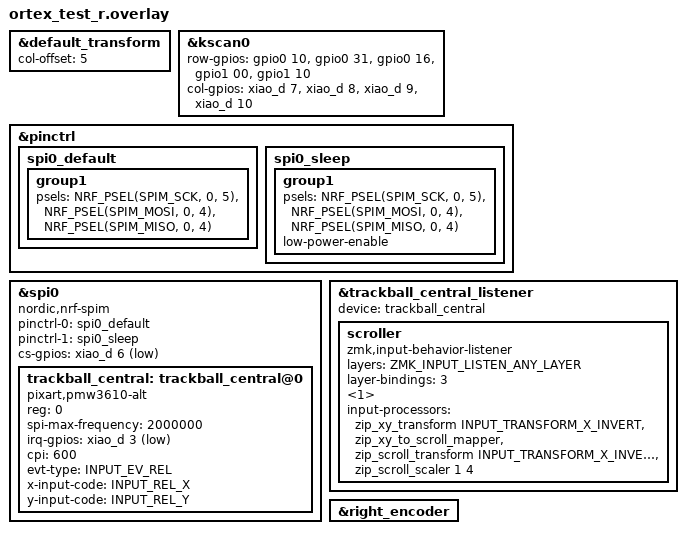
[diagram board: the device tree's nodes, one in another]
#include "ortex_test.dtsi"
#include <input/processors.dtsi>
#include <zephyr/dt-bindings/input/input-event-codes.h>

&default_transform {
    col-offset = <5>;
};

&kscan0 {        
        row-gpios
            = <&gpio0 10 GPIO_ACTIVE_HIGH>
            , <&gpio0 31 GPIO_ACTIVE_HIGH> 
            , <&gpio0 16 GPIO_ACTIVE_HIGH> 
            , <&gpio1 00 GPIO_ACTIVE_HIGH> 
            , <&gpio1 10 GPIO_ACTIVE_HIGH> 
            ;

        col-gpios
            = <&xiao_d 7 GPIO_ACTIVE_HIGH>
            , <&xiao_d 8 GPIO_ACTIVE_HIGH> 
            , <&xiao_d 9 GPIO_ACTIVE_HIGH> 
            , <&xiao_d 10 GPIO_ACTIVE_HIGH> 
            ;
};


&pinctrl {
    spi0_default: spi0_default {    //通常時(SPI通信中)のピン構成
        group1 {
            psels = <NRF_PSEL(SPIM_SCK, 0, 5)>, //P0.05を指定(SCLK)
                <NRF_PSEL(SPIM_MOSI, 0, 4)>,    //P0.04を指定(SDIOだからMOSI,MISO両方の役割を担う)
                <NRF_PSEL(SPIM_MISO, 0, 4)>;
        };
    };

    spi0_sleep: spi0_sleep {    //スリープ時のピン構成(省電力)
        group1 {
            psels = <NRF_PSEL(SPIM_SCK, 0, 5)>,
                <NRF_PSEL(SPIM_MOSI, 0, 4)>,
                <NRF_PSEL(SPIM_MISO, 0, 4)>;
            low-power-enable;
        };
    };
};


&spi0 {
    status = "okay";
    compatible = "nordic,nrf-spim"; //マイコンがnRFシリーズ
    pinctrl-0 = <&spi0_default>;
    pinctrl-1 = <&spi0_sleep>;
    pinctrl-names = "default", "sleep";
    cs-gpios = <&xiao_d 6 GPIO_ACTIVE_LOW>;  //P1.11を指定(CS)

    trackball_central: trackball_central@0 {
        status = "okay";
        compatible = "pixart,pmw3610-alt";  //トラボセンサ用のドライバとバインド
        reg = <0>;
        spi-max-frequency = <2000000>;
        irq-gpios = <&xiao_d 3 (GPIO_ACTIVE_LOW | GPIO_PULL_UP)>; //P0.29を指定(MOTION)
        cpi = <600>;
        //swap-xy;
        //invert-x; //COROPIT版ではコメントアウトを外す
        //invert-y; //COROPIT版ではコメントアウトを外す
        evt-type = <INPUT_EV_REL>;
        x-input-code = <INPUT_REL_X>;
        y-input-code = <INPUT_REL_Y>;
    };
};


// Overrides for the input listener node
&trackball_central_listener {
    status = "okay";
    device = <&trackball_central>;

    scroller {
        compatible = "zmk,input-behavior-listener";
        layers = <ZMK_INPUT_LISTEN_ANY_LAYER>;
        layer-bindings = <3>;
        layer-bindings-len <1>;
        input-processors = 
            // <&zip_xy_transform INPUT_TRANSFORM_XY_SWAP>,        //X軸とY軸の入れ替え
            <&zip_xy_transform INPUT_TRANSFORM_X_INVERT>,       //X軸反転
            <&zip_xy_to_scroll_mapper>,                         //スクロールモードに変更
            <&zip_scroll_transform INPUT_TRANSFORM_X_INVERT>,   //スクロールのX軸反転
            <&zip_scroll_scaler 1 4>;                           //スクロール量を1/4倍
    };
};

&right_encoder {
    status = "okay";
};
